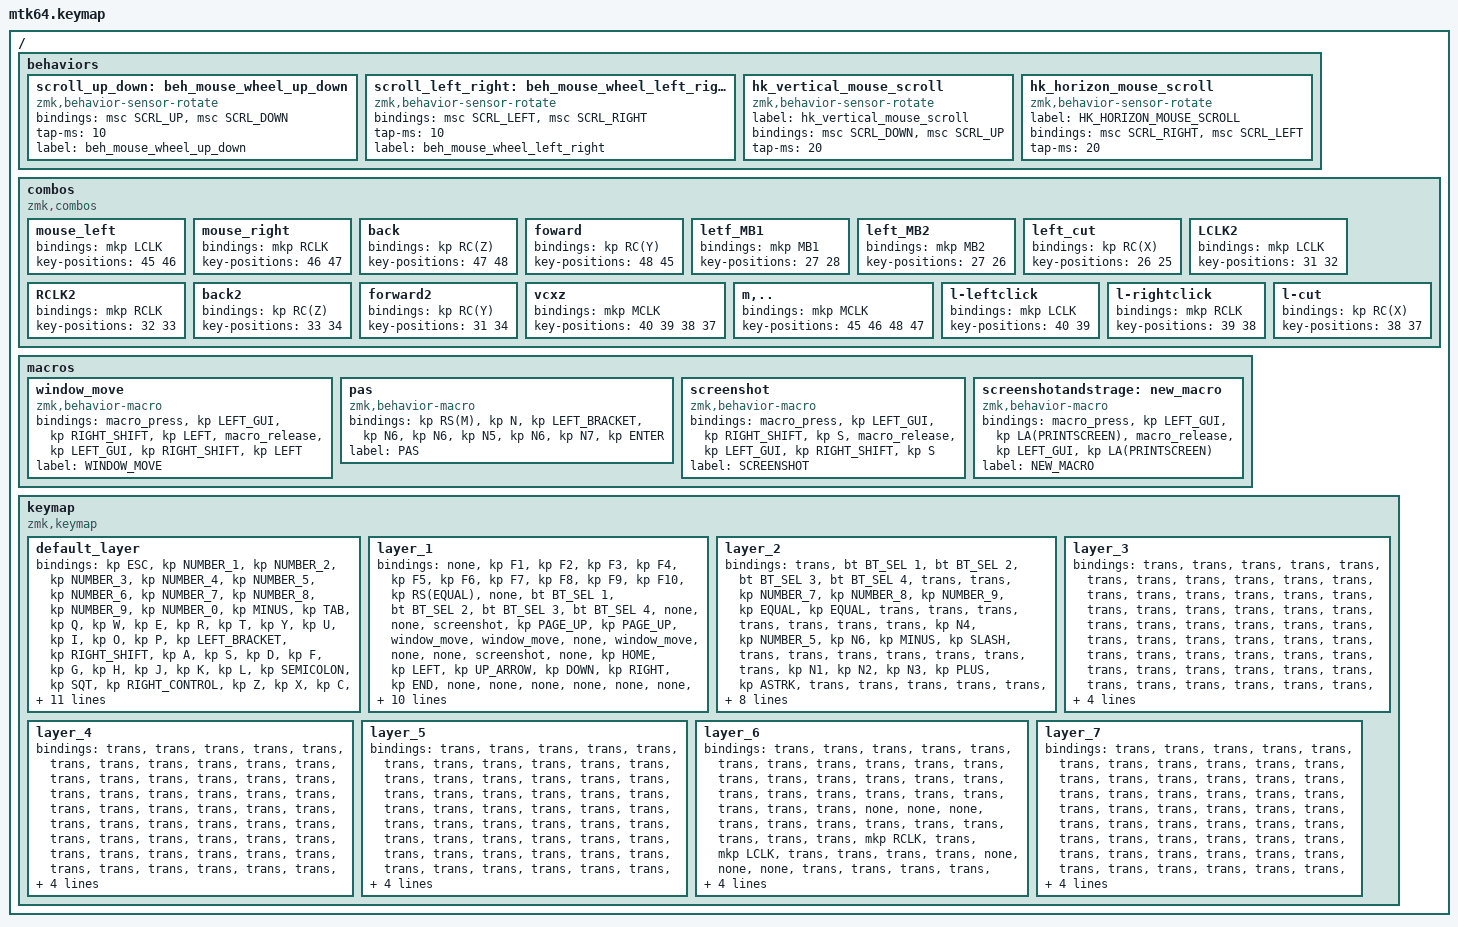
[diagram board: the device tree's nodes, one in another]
#include "keycode_japanese.h"

// .keymapファイルに以下を追記すると、クリックした後250ミリ秒後にAMLが解除されます。ここから

#include <input/processors.dtsi>
#include <behaviors.dtsi>
#include <dt-bindings/zmk/bt.h>
#include <dt-bindings/zmk/keys.h>
#include <dt-bindings/zmk/pointing.h>

// &mkp_input_listener { input-processors = <&zip_temp_layer 6 250>; };
//  .keymapファイルに以下を追記すると、クリックした後250ミリ秒後にAMLが解除されます。ここまで
// スクロール量の設定

#define ZMK_POINTING_DEFAULT_SCRL_VAL 100

/ {
    behaviors {
        // 垂直スクロール用のbehaviorの設定

        scroll_up_down: beh_mouse_wheel_up_down {
            compatible = "zmk,behavior-sensor-rotate";
            #sensor-binding-cells = <0>;
            bindings = <&msc SCRL_UP>, <&msc SCRL_DOWN>;

            tap-ms = <10>; // スクロールのタップ時間
            label = "beh_mouse_wheel_up_down";
        };

        // 水平スクロール用のbehaviorの設定

        scroll_left_right: beh_mouse_wheel_left_right {
            compatible = "zmk,behavior-sensor-rotate";
            #sensor-binding-cells = <0>;
            bindings = <&msc SCRL_LEFT>, <&msc SCRL_RIGHT>;

            tap-ms = <10>; // スクロールのタップ時間
            label = "beh_mouse_wheel_left_right";
        };

        hk_vertical_mouse_scroll: hk_vertical_mouse_scroll {
            compatible = "zmk,behavior-sensor-rotate";
            label = "hk_vertical_mouse_scroll";
            #sensor-binding-cells = <0>;
            bindings = <&msc SCRL_DOWN>, <&msc SCRL_UP>;

            tap-ms = <20>;
        };

        hk_horizon_mouse_scroll: hk_horizon_mouse_scroll {
            compatible = "zmk,behavior-sensor-rotate";
            label = "HK_HORIZON_MOUSE_SCROLL";
            #sensor-binding-cells = <0>;
            bindings = <&msc SCRL_RIGHT>, <&msc SCRL_LEFT>;

            tap-ms = <20>;
        };
    };
};

/ {
    combos {
        compatible = "zmk,combos";

        mouse_left {
            bindings = <&mkp LCLK>;
            key-positions = <45 46>;
        };

        mouse_right {
            bindings = <&mkp RCLK>;
            key-positions = <46 47>;
        };

        back {
            bindings = <&kp RC(Z)>;
            key-positions = <47 48>;
        };

        foward {
            bindings = <&kp RC(Y)>;
            key-positions = <48 45>;
        };

        letf_MB1 {
            bindings = <&mkp MB1>;
            key-positions = <27 28>;
        };

        left_MB2 {
            bindings = <&mkp MB2>;
            key-positions = <27 26>;
        };

        left_cut {
            bindings = <&kp RC(X)>;
            key-positions = <26 25>;
        };

        LCLK2 {
            bindings = <&mkp LCLK>;
            key-positions = <31 32>;
        };

        RCLK2 {
            bindings = <&mkp RCLK>;
            key-positions = <32 33>;
        };

        back2 {
            bindings = <&kp RC(Z)>;
            key-positions = <33 34>;
        };

        forward2 {
            bindings = <&kp RC(Y)>;
            key-positions = <31 34>;
        };

        vcxz {
            bindings = <&mkp MCLK>;
            key-positions = <40 39 38 37>;
        };

        m,.. {
            bindings = <&mkp MCLK>;
            key-positions = <45 46 48 47>;
        };

        l-leftclick {
            bindings = <&mkp LCLK>;
            key-positions = <40 39>;
        };

        l-rightclick {
            bindings = <&mkp RCLK>;
            key-positions = <39 38>;
        };

        l-cut {
            bindings = <&kp RC(X)>;
            key-positions = <38 37>;
        };
    };

    macros {
        window_move: window_move {
            compatible = "zmk,behavior-macro";
            #binding-cells = <0>;
            bindings =
                <&macro_press>,
                <&kp LEFT_GUI &kp RIGHT_SHIFT &kp LEFT>,
                <&macro_release>,
                <&kp LEFT_GUI &kp RIGHT_SHIFT &kp LEFT>;

            label = "WINDOW_MOVE";
        };

        pas: pas {
            compatible = "zmk,behavior-macro";
            #binding-cells = <0>;
            bindings = <&kp RS(M) &kp N &kp LEFT_BRACKET &kp N6 &kp N6 &kp N5 &kp N6 &kp N7 &kp ENTER>;
            label = "PAS";
        };

        screenshot: screenshot {
            compatible = "zmk,behavior-macro";
            #binding-cells = <0>;
            bindings =
                <&macro_press>,
                <&kp LEFT_GUI &kp RIGHT_SHIFT &kp S>,
                <&macro_release>,
                <&kp LEFT_GUI &kp RIGHT_SHIFT &kp S>;

            label = "SCREENSHOT";
        };

        screenshotandstrage: new_macro {
            compatible = "zmk,behavior-macro";
            #binding-cells = <0>;
            bindings =
                <&macro_press>,
                <&kp LEFT_GUI &kp LA(PRINTSCREEN)>,
                <&macro_release>,
                <&kp LEFT_GUI &kp LA(PRINTSCREEN)>;

            label = "NEW_MACRO";
        };
    };

    keymap {
        compatible = "zmk,keymap";

        default_layer {
            bindings = <
&kp ESC  &kp NUMBER_1  &kp NUMBER_2  &kp NUMBER_3  &kp NUMBER_4  &kp NUMBER_5  &kp NUMBER_6  &kp NUMBER_7  &kp NUMBER_8  &kp NUMBER_9  &kp NUMBER_0  &kp MINUS  &kp TAB  &kp Q  &kp W  &kp E  &kp R  &kp T  &kp Y  &kp U  &kp I  &kp O  &kp P  &kp LEFT_BRACKET  &kp RIGHT_SHIFT  &kp A  &kp S  &kp D  &kp F  &kp G  &kp H  &kp J  &kp K  &kp L  &kp SEMICOLON  &kp SQT  &kp RIGHT_CONTROL  &kp Z  &kp X  &kp C  &kp V  &kp B  &kp RIGHT_BRACKET  &kp BACKSLASH  &kp N  &kp M  &kp COMMA  &kp DOT  &mt RS(INT1) SLASH  &kp EQUAL  &kp RIGHT_ALT  &kp LEFT_COMMAND  &lt 1 SPACE  &kp BACKSPACE  &kp LANGUAGE_1  &lt 1 ENTER  &kp INT1  &mt RCTRL ESCAPE  &pas  &kp LG(L)  &kp DELETE  &kp LANGUAGE_2  &none  &none  &mkp LCLK  &mkp RCLK  &mo 1  &mo 2  &mo 3  &mo 1  &mo 2  &mo 3  &mo 1  &mo 2  &mo 3
            >;

            sensor-bindings =
                <&hk_horizon_mouse_scroll>,
                <&hk_vertical_mouse_scroll>;
        };

        layer_1 {
            bindings = <
&none  &kp F1  &kp F2  &kp F3  &kp F4  &kp F5  &kp F6  &kp F7  &kp F8  &kp F9  &kp F10  &kp RS(EQUAL)  &none  &bt BT_SEL 1  &bt BT_SEL 2  &bt BT_SEL 3  &bt BT_SEL 4  &none  &none  &screenshot  &kp PAGE_UP  &kp PAGE_UP  &window_move  &window_move  &none  &window_move  &none  &none  &screenshot  &none  &kp HOME  &kp LEFT  &kp UP_ARROW  &kp DOWN  &kp RIGHT  &kp END  &none  &none  &none  &none  &none  &none  &none  &screenshotandstrage  &kp RC(X)  &kp RC(C)  &kp RC(V)  &kp RC(Z)  &kp RC(Y)  &kp DELETE  &none  &none  &none  &none  &none  &none  &none  &kp BACKSPACE  &none  &none  &none  &none  &trans  &trans  &none  &none  &trans  &trans  &trans  &trans  &trans  &trans  &trans  &trans  &trans
            >;

            sensor-bindings =
                <&inc_dec_kp C_BRI_DEC C_BRIGHTNESS_INC>,
                <&inc_dec_kp C_VOL_DN C_VOLUME_UP>;
        };

        layer_2 {
            bindings = <
&trans  &bt BT_SEL 1  &bt BT_SEL 2  &bt BT_SEL 3  &bt BT_SEL 4  &trans  &trans  &kp NUMBER_7  &kp NUMBER_8  &kp NUMBER_9  &kp EQUAL  &kp EQUAL  &trans  &trans  &trans  &trans  &trans  &trans  &trans  &kp N4  &kp NUMBER_5  &kp N6  &kp MINUS  &kp SLASH  &trans  &trans  &trans  &trans  &trans  &trans  &trans  &kp N1  &kp N2  &kp N3  &kp PLUS  &kp ASTRK  &trans  &trans  &trans  &trans  &trans  &trans  &trans  &trans  &trans  &kt NUMBER_0  &kp COMMA  &kp PERIOD  &kp SLASH  &trans  &trans  &trans  &trans  &trans  &trans  &none  &trans  &trans  &trans  &trans  &trans  &trans  &trans  &trans  &trans  &trans  &trans  &trans  &trans  &trans  &trans  &trans  &trans  &trans  &trans
            >;

            sensor-bindings =
                <&inc_dec_kp LEFT_ARROW RIGHT>,
                <&inc_dec_kp DOWN UP_ARROW>;
        };

        layer_3 {
            bindings = <
&trans  &trans  &trans  &trans  &trans  &trans  &trans  &trans  &trans  &trans  &trans  &trans  &trans  &trans  &trans  &trans  &trans  &trans  &trans  &trans  &trans  &trans  &trans  &trans  &trans  &trans  &trans  &trans  &trans  &trans  &trans  &trans  &trans  &trans  &trans  &trans  &trans  &trans  &trans  &trans  &trans  &trans  &trans  &trans  &trans  &trans  &trans  &trans  &trans  &trans  &trans  &trans  &trans  &trans  &trans  &trans  &trans  &trans  &trans  &trans  &trans  &trans  &trans  &trans  &trans  &trans  &trans  &trans  &trans  &trans  &trans  &trans  &trans  &trans  &trans
            >;
        };

        layer_4 {
            bindings = <
&trans  &trans  &trans  &trans  &trans  &trans  &trans  &trans  &trans  &trans  &trans  &trans  &trans  &trans  &trans  &trans  &trans  &trans  &trans  &trans  &trans  &trans  &trans  &trans  &trans  &trans  &trans  &trans  &trans  &trans  &trans  &trans  &trans  &trans  &trans  &trans  &trans  &trans  &trans  &trans  &trans  &trans  &trans  &trans  &trans  &trans  &trans  &trans  &trans  &trans  &trans  &trans  &trans  &trans  &trans  &trans  &trans  &trans  &trans  &trans  &trans  &trans  &trans  &trans  &trans  &trans  &trans  &trans  &trans  &trans  &trans  &trans  &trans  &trans  &trans
            >;
        };

        layer_5 {
            bindings = <
&trans  &trans  &trans  &trans  &trans  &trans  &trans  &trans  &trans  &trans  &trans  &trans  &trans  &trans  &trans  &trans  &trans  &trans  &trans  &trans  &trans  &trans  &trans  &trans  &trans  &trans  &trans  &trans  &trans  &trans  &trans  &trans  &trans  &trans  &trans  &trans  &trans  &trans  &trans  &trans  &trans  &trans  &trans  &trans  &trans  &trans  &trans  &trans  &trans  &trans  &trans  &trans  &trans  &trans  &trans  &trans  &trans  &trans  &trans  &trans  &trans  &trans  &trans  &trans  &trans  &trans  &trans  &trans  &trans  &trans  &trans  &trans  &trans  &trans  &trans
            >;
        };

        layer_6 {
            bindings = <
&trans  &trans  &trans  &trans  &trans  &trans  &trans  &trans  &trans  &trans  &trans  &trans  &trans  &trans  &trans  &trans  &trans  &trans  &trans  &trans  &trans  &trans  &trans  &trans  &trans  &trans  &none  &none  &none  &trans  &trans  &trans  &trans  &trans  &trans  &trans  &trans  &trans  &mkp RCLK  &trans  &mkp LCLK  &trans  &trans  &trans  &trans  &none  &none  &none  &trans  &trans  &trans  &trans  &trans  &trans  &trans  &trans  &trans  &trans  &trans  &trans  &trans  &trans  &trans  &trans  &trans  &trans  &trans  &trans  &trans  &trans  &trans  &trans  &trans  &trans  &trans
            >;
        };

        layer_7 {
            bindings = <
&trans  &trans  &trans  &trans  &trans  &trans  &trans  &trans  &trans  &trans  &trans  &trans  &trans  &trans  &trans  &trans  &trans  &trans  &trans  &trans  &trans  &trans  &trans  &trans  &trans  &trans  &trans  &trans  &trans  &trans  &trans  &trans  &trans  &trans  &trans  &trans  &trans  &trans  &trans  &trans  &trans  &trans  &trans  &trans  &trans  &trans  &trans  &trans  &trans  &trans  &trans  &trans  &trans  &trans  &trans  &trans  &trans  &trans  &trans  &trans  &trans  &trans  &trans  &trans  &trans  &trans  &trans  &trans  &trans  &trans  &trans  &trans  &trans  &trans  &trans
            >;
        };
    };
};
